AUTOSAR XML (schema 4-2-1)
package /VehicleProject
  system System
package /Cluster
  can cluster CAN00: protocol-name=CAN  # PIHIL
    can physical channel CHNL: comm-connectors=CN_CAN00
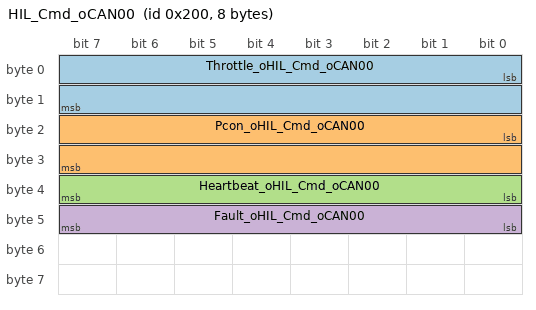
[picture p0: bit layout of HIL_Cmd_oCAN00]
      frame HIL_Cmd_oCAN00: id 0x200, from S32K144, frame-length=8, can-addressing-mode=STANDARD
        pdu HIL_Cmd_oCAN00: length=8, unused-bit-pattern=0
          signal Throttle_oHIL_Cmd_oCAN00: start 0, 16 bit, little-endian, base-type=uint16, compu-method=CM_Throttle, transfer-property=PENDING
          signal Pcon_oHIL_Cmd_oCAN00: start 16, 16 bit, little-endian, base-type=uint16, compu-method=CM_Pcon, unit=U_MPa, transfer-property=PENDING
          signal Heartbeat_oHIL_Cmd_oCAN00: start 32, 8 bit, little-endian, base-type=uint8, data-constr=DC_Heartbeat, transfer-property=PENDING
          signal Fault_oHIL_Cmd_oCAN00: start 40, 8 bit, little-endian, base-type=uint8, data-constr=DC_Fault, transfer-property=PENDING
      frame HIL_Vx_oCAN00: id 0x100, to S32K144, frame-length=8, can-addressing-mode=STANDARD
        pdu HIL_Vx_oCAN00: length=8, unused-bit-pattern=0
          signal Vx_oHIL_Vx_oCAN00: start 0, 16 bit, little-endian, base-type=sint16, compu-method=CM_Vx, unit=U_kmYh, transfer-property=PENDING, to S32K144
          signal Cnt_oHIL_Vx_oCAN00: start 16, 16 bit, little-endian, base-type=uint16, data-constr=DC_Cnt, transfer-property=PENDING, to S32K144
package /ECU
  ecu instance S32K144: associated-com-i-pdu-group=[S32K144_oCAN00_Rx, S32K144_oCAN00_Tx]
    can communication controller CT_CAN00
    can communication connector CN_CAN00: comm-controller=CT_CAN00
package /IPDUGroup
  i signal i pdu group S32K144_oCAN00_Rx: communication-direction=IN, i-signal-i-pdus=HIL_Vx_oCAN00
  i signal i pdu group S32K144_oCAN00_Tx: communication-direction=OUT, i-signal-i-pdus=HIL_Cmd_oCAN00
